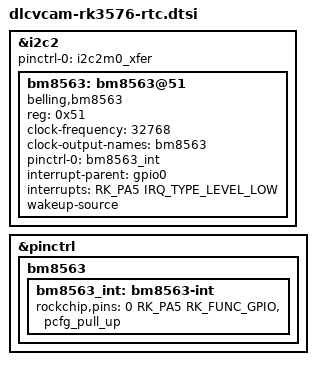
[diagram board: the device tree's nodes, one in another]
/********************************************************************
 * SPDX-License-Identifier: (GPL-2.0+ OR MIT)
 * 
 * Copyright (c) 2023 Rockchip Electronics Co., Ltd.
 * Copyright (c) 2026 LCKFB <lckfb@sz-jlc.com>
 *********************************************************************
 * Wiki-(Chinese)：https://wiki.lckfb.com/
 * Wiki-(English)：https://wiki.lckfb.com/en/
 *********************************************************************/

/*-----------------------------------------------------------
 * I2C2 Bus and Mounted Device Node Configuration
 * status: Enable I2C2 bus
 * pinctrl-names/pinctrl-0: Bind default I2C2 signal pin configuration
 *----------------------------------------------------------*/
&i2c2 {
	status = "okay";

	pinctrl-names = "default";
	pinctrl-0 = <&i2c2m0_xfer>;

	/*
	 * BM8563EHA RTC Chip Node
	 * compatible: Device compatible strings for Belling BM8563EHA
		 *   (PCF8563-compatible, also matches haoyu,hym8563 fallback)
	 * reg: I2C address is 0x51
	 * #clock-cells: Number of cells when providing clock resources (usually 0)
	 * clock-frequency: RTC crystal frequency is 32.768KHz
	 * clock-output-names: Exported clock name, for reference by other devices
	 * pinctrl-names/pinctrl-0: Bind RTC INT interrupt pin configuration
	 * interrupt-parent: Specify interrupt controller as gpio0
	 * interrupts: INT interrupt pin is GPIO0 PA5, low level trigger
	 * wakeup-source: Supports power-off wakeup function
	 * status: Enable RTC chip
	 */
	bm8563: bm8563@51 {
        status = "okay";
		compatible = "belling,bm8563", "haoyu,hym8563";
		reg = <0x51>;
		#clock-cells = <0>;
		clock-frequency = <32768>;
		clock-output-names = "bm8563";
		pinctrl-names = "default";
		pinctrl-0 = <&bm8563_int>;
		interrupt-parent = <&gpio0>;
		interrupts = <RK_PA5 IRQ_TYPE_LEVEL_LOW>;
		wakeup-source;
	};
};

/*-----------------------------------------------------------
 * Pin Multiplexing Configuration (Pinmux)
 * bm8563_int sub-node under bm8563 node
 * rockchip,pins: Specify GPIO0 PA5 for RTC INT interrupt, function is GPIO, configured with pull-up
 *----------------------------------------------------------*/
&pinctrl {
	bm8563 {
		bm8563_int: bm8563-int {
			rockchip,pins = <0 RK_PA5 RK_FUNC_GPIO &pcfg_pull_up>;
		};
	};
};

